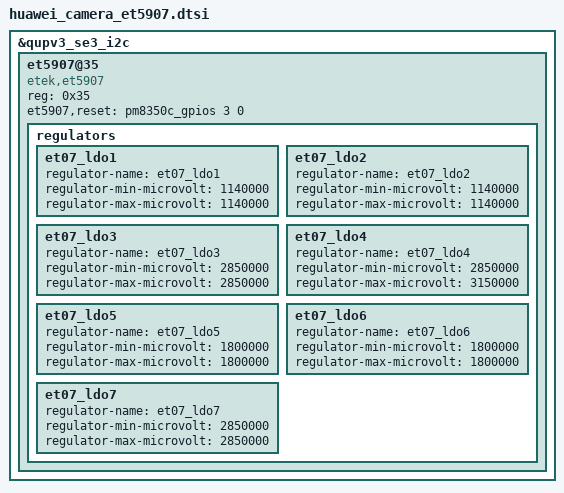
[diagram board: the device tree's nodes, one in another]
&qupv3_se3_i2c {
	status = "ok";
	et5907@35 {
		compatible = "etek,et5907";
		reg = <0x35>;	/* (0x6A)8bit (0x35)7bit */
		et5907,reset = <&pm8350c_gpios 3 0>;
		regulators {
			et07_ldo1: et07_ldo1 {
				regulator-name = "et07_ldo1";
				regulator-min-microvolt = <1140000>;
				regulator-max-microvolt = <1140000>;
			};
			et07_ldo2: et07_ldo2 {
				regulator-name = "et07_ldo2";
				regulator-min-microvolt = <1140000>;
				regulator-max-microvolt = <1140000>;
			};
			et07_ldo3: et07_ldo3 {
				regulator-name = "et07_ldo3";
				regulator-min-microvolt = <2850000>;
				regulator-max-microvolt = <2850000>;
			};
			et07_ldo4: et07_ldo4 {
				regulator-name = "et07_ldo4";
				regulator-min-microvolt = <2850000>;
				regulator-max-microvolt = <3150000>;
			};
			et07_ldo5: et07_ldo5 {
				regulator-name = "et07_ldo5";
				regulator-min-microvolt = <1800000>;
				regulator-max-microvolt = <1800000>;
			};
			et07_ldo6: et07_ldo6 {
				regulator-name = "et07_ldo6";
				regulator-min-microvolt = <1800000>;
				regulator-max-microvolt = <1800000>;
			};
			et07_ldo7: et07_ldo7 {
				regulator-name = "et07_ldo7";
				regulator-min-microvolt = <2850000>;
				regulator-max-microvolt = <2850000>;
			};
		};
	};
};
